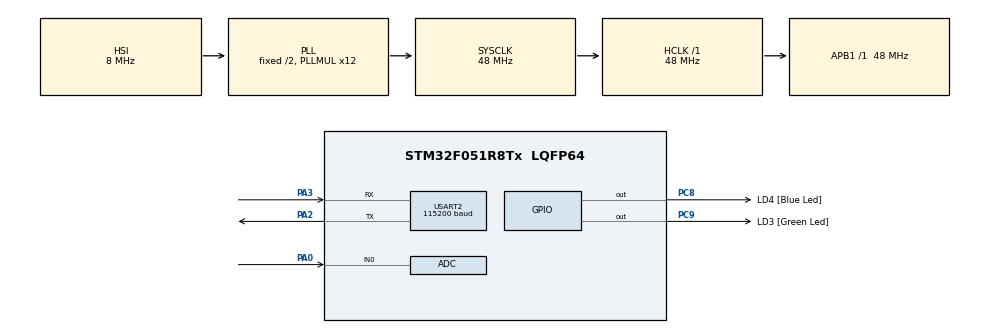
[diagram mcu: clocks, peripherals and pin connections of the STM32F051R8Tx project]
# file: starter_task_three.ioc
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Mcu.Family=STM32F0
Mcu.Name=STM32F051R8Tx
Mcu.Package=LQFP64
PA0.Mode=IN0
PA0.Signal=ADC_IN0
PA13.GPIO_Label=SWDIO
PA13.Mode=Serial_Wire
PA13.Signal=SYS_SWDIO
PA14.GPIO_Label=SWCLK
PA14.Mode=Serial_Wire
PA14.Signal=SYS_SWCLK
PA2.Mode=Asynchronous
PA2.Signal=USART2_TX
PA3.Mode=Asynchronous
PA3.Signal=USART2_RX
PC8.GPIO_Label=LD4 [Blue Led]
PC8.Signal=GPIO_Output
PC9.GPIO_Label=LD3 [Green Led]
PC9.Signal=GPIO_Output
ProjectManager.HeapSize=0x200
ProjectManager.StackSize=0x400
ProjectManager.TargetToolchain=STM32CubeIDE
RCC.AHBFreq_Value=48000000
RCC.APB1Freq_Value=48000000
RCC.APB1TimFreq_Value=48000000
RCC.HCLKFreq_Value=48000000
RCC.PLLMUL=RCC_PLL_MUL12
RCC.SYSCLKFreq_VALUE=48000000
RCC.SYSCLKSource=RCC_SYSCLKSOURCE_PLLCLK
RTC.Date=7
RTC.Hours=2
RTC.Minutes=50
RTC.Month=RTC_MONTH_MAY
RTC.WeekDay=RTC_WEEKDAY_TUESDAY
RTC.Year=24
USART2.BaudRate=115200
USART2.VirtualMode-Asynchronous=VM_ASYNC
VP_RTC_VS_RTC_Activate.Mode=RTC_Enabled
VP_RTC_VS_RTC_Calendar.Mode=RTC_Calendar
board=STM32F0DISCOVERY

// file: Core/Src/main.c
/* USER CODE BEGIN Header */
/**
  ******************************************************************************
  * @file           : main.c
  * @brief          : Main program body
  ******************************************************************************
  * @attention
  *
  * Copyright (c) 2024 STMicroelectronics.
  * All rights reserved.
  *
  * This software is licensed under terms that can be found in the LICENSE file
  * in the root directory of this software component.
  * If no LICENSE file comes with this software, it is provided AS-IS.
  *
  ******************************************************************************
  */
/* USER CODE END Header */
#include "main.h"

/* USER CODE BEGIN Includes */
#include <stdint.h>
#include <stdio.h>
#include <string.h>

/* USER CODE END Includes */

ADC_HandleTypeDef hadc;

RTC_HandleTypeDef hrtc;

UART_HandleTypeDef huart2;

void SystemClock_Config(void);
static void MX_GPIO_Init(void);
static void MX_RTC_Init(void);
static void MX_ADC_Init(void);
static void MX_USART2_UART_Init(void);

int main(void)
{

  /* MCU Configuration--------------------------------------------------------*/

  /* Reset of all peripherals, Initializes the Flash interface and the Systick. */
  HAL_Init();

  /* Configure the system clock */
  SystemClock_Config();

  /* Initialize all configured peripherals */
  MX_GPIO_Init();
  MX_RTC_Init();
  MX_ADC_Init();
  MX_USART2_UART_Init();
  /* USER CODE BEGIN 2 */
  char uart_buf[100];
  int uart_buf_len;
  uint8_t format = RTC_FORMAT_BIN;
  RTC_TimeTypeDef sTime = {0};
  RTC_DateTypeDef sDate = {0};

  /* USER CODE END 2 */

  /* Infinite loop */
  while (1)
  {

    /* USER CODE BEGIN 3 */
	  HAL_RTC_GetTime(&hrtc, &sTime, format);
	  HAL_RTC_GetDate(&hrtc, &sDate, format);
	  uart_buf_len = sprintf(uart_buf, "20%u-%u-%u %u:%u:%u\r\n", sDate.Year, sDate.Month,
			  sDate.Date, sTime.Hours, sTime.Minutes, sTime.Seconds);
	  HAL_UART_Transmit(&huart2, (uint8_t*)uart_buf, uart_buf_len, 1000);

	  HAL_Delay(500);
  }
  /* USER CODE END 3 */
}

void SystemClock_Config(void)
{
  RCC_OscInitTypeDef RCC_OscInitStruct = {0};
  RCC_ClkInitTypeDef RCC_ClkInitStruct = {0};
  RCC_PeriphCLKInitTypeDef PeriphClkInit = {0};

  /** Initializes the RCC Oscillators according to the specified parameters
  * in the RCC_OscInitTypeDef structure.
  */
  RCC_OscInitStruct.OscillatorType = RCC_OSCILLATORTYPE_HSI|RCC_OSCILLATORTYPE_HSI14
                              |RCC_OSCILLATORTYPE_LSI;
  RCC_OscInitStruct.HSIState = RCC_HSI_ON;
  RCC_OscInitStruct.HSI14State = RCC_HSI14_ON;
  RCC_OscInitStruct.HSICalibrationValue = RCC_HSICALIBRATION_DEFAULT;
  RCC_OscInitStruct.HSI14CalibrationValue = 16;
  RCC_OscInitStruct.LSIState = RCC_LSI_ON;
  RCC_OscInitStruct.PLL.PLLState = RCC_PLL_ON;
  RCC_OscInitStruct.PLL.PLLSource = RCC_PLLSOURCE_HSI;
  RCC_OscInitStruct.PLL.PLLMUL = RCC_PLL_MUL12;
  RCC_OscInitStruct.PLL.PREDIV = RCC_PREDIV_DIV1;
  if (HAL_RCC_OscConfig(&RCC_OscInitStruct) != HAL_OK)
  {
    Error_Handler();
  }

  /** Initializes the CPU, AHB and APB buses clocks
  */
  RCC_ClkInitStruct.ClockType = RCC_CLOCKTYPE_HCLK|RCC_CLOCKTYPE_SYSCLK
                              |RCC_CLOCKTYPE_PCLK1;
  RCC_ClkInitStruct.SYSCLKSource = RCC_SYSCLKSOURCE_PLLCLK;
  RCC_ClkInitStruct.AHBCLKDivider = RCC_SYSCLK_DIV1;
  RCC_ClkInitStruct.APB1CLKDivider = RCC_HCLK_DIV1;

  if (HAL_RCC_ClockConfig(&RCC_ClkInitStruct, FLASH_LATENCY_1) != HAL_OK)
  {
    Error_Handler();
  }
  PeriphClkInit.PeriphClockSelection = RCC_PERIPHCLK_RTC;
  PeriphClkInit.RTCClockSelection = RCC_RTCCLKSOURCE_LSI;
  if (HAL_RCCEx_PeriphCLKConfig(&PeriphClkInit) != HAL_OK)
  {
    Error_Handler();
  }
}

static void MX_ADC_Init(void)
{

  ADC_ChannelConfTypeDef sConfig = {0};

  /** Configure the global features of the ADC (Clock, Resolution, Data Alignment and number of conversion)
  */
  hadc.Instance = ADC1;
  hadc.Init.ClockPrescaler = ADC_CLOCK_ASYNC_DIV1;
  hadc.Init.Resolution = ADC_RESOLUTION_12B;
  hadc.Init.DataAlign = ADC_DATAALIGN_RIGHT;
  hadc.Init.ScanConvMode = ADC_SCAN_DIRECTION_FORWARD;
  hadc.Init.EOCSelection = ADC_EOC_SINGLE_CONV;
  hadc.Init.LowPowerAutoWait = DISABLE;
  hadc.Init.LowPowerAutoPowerOff = DISABLE;
  hadc.Init.ContinuousConvMode = DISABLE;
  hadc.Init.DiscontinuousConvMode = DISABLE;
  hadc.Init.ExternalTrigConv = ADC_SOFTWARE_START;
  hadc.Init.ExternalTrigConvEdge = ADC_EXTERNALTRIGCONVEDGE_NONE;
  hadc.Init.DMAContinuousRequests = DISABLE;
  hadc.Init.Overrun = ADC_OVR_DATA_PRESERVED;
  if (HAL_ADC_Init(&hadc) != HAL_OK)
  {
    Error_Handler();
  }

  /** Configure for the selected ADC regular channel to be converted.
  */
  sConfig.Channel = ADC_CHANNEL_0;
  sConfig.Rank = ADC_RANK_CHANNEL_NUMBER;
  sConfig.SamplingTime = ADC_SAMPLETIME_1CYCLE_5;
  if (HAL_ADC_ConfigChannel(&hadc, &sConfig) != HAL_OK)
  {
    Error_Handler();
  }

}

static void MX_RTC_Init(void)
{

  RTC_TimeTypeDef sTime = {0};
  RTC_DateTypeDef sDate = {0};

  /** Initialize RTC Only
  */
  hrtc.Instance = RTC;
  hrtc.Init.HourFormat = RTC_HOURFORMAT_24;
  hrtc.Init.AsynchPrediv = 127;
  hrtc.Init.SynchPrediv = 255;
  hrtc.Init.OutPut = RTC_OUTPUT_DISABLE;
  hrtc.Init.OutPutPolarity = RTC_OUTPUT_POLARITY_HIGH;
  hrtc.Init.OutPutType = RTC_OUTPUT_TYPE_OPENDRAIN;
  if (HAL_RTC_Init(&hrtc) != HAL_OK)
  {
    Error_Handler();
  }

  /** Initialize RTC and set the Time and Date
  */
  sTime.Hours = 0x2;
  sTime.Minutes = 0x50;
  sTime.Seconds = 0x0;
  sTime.DayLightSaving = RTC_DAYLIGHTSAVING_NONE;
  sTime.StoreOperation = RTC_STOREOPERATION_RESET;
  if (HAL_RTC_SetTime(&hrtc, &sTime, RTC_FORMAT_BCD) != HAL_OK)
  {
    Error_Handler();
  }
  sDate.WeekDay = RTC_WEEKDAY_TUESDAY;
  sDate.Month = RTC_MONTH_MAY;
  sDate.Date = 0x7;
  sDate.Year = 0x24;

  if (HAL_RTC_SetDate(&hrtc, &sDate, RTC_FORMAT_BCD) != HAL_OK)
  {
    Error_Handler();
  }

}

static void MX_USART2_UART_Init(void)
{

  huart2.Instance = USART2;
  huart2.Init.BaudRate = 115200;
  huart2.Init.WordLength = UART_WORDLENGTH_8B;
  huart2.Init.StopBits = UART_STOPBITS_1;
  huart2.Init.Parity = UART_PARITY_NONE;
  huart2.Init.Mode = UART_MODE_TX_RX;
  huart2.Init.HwFlowCtl = UART_HWCONTROL_NONE;
  huart2.Init.OverSampling = UART_OVERSAMPLING_16;
  huart2.Init.OneBitSampling = UART_ONE_BIT_SAMPLE_DISABLE;
  huart2.AdvancedInit.AdvFeatureInit = UART_ADVFEATURE_NO_INIT;
  if (HAL_UART_Init(&huart2) != HAL_OK)
  {
    Error_Handler();
  }

}

static void MX_GPIO_Init(void)
{
  GPIO_InitTypeDef GPIO_InitStruct = {0};

  /* GPIO Ports Clock Enable */
  __HAL_RCC_GPIOA_CLK_ENABLE();
  __HAL_RCC_GPIOC_CLK_ENABLE();

  /*Configure GPIO pin Output Level */
  HAL_GPIO_WritePin(GPIOC, LD4_Pin|LD3_Pin, GPIO_PIN_RESET);

  /*Configure GPIO pins : LD4_Pin LD3_Pin */
  GPIO_InitStruct.Pin = LD4_Pin|LD3_Pin;
  GPIO_InitStruct.Mode = GPIO_MODE_OUTPUT_PP;
  GPIO_InitStruct.Pull = GPIO_NOPULL;
  GPIO_InitStruct.Speed = GPIO_SPEED_FREQ_LOW;
  HAL_GPIO_Init(GPIOC, &GPIO_InitStruct);

}

void Error_Handler(void)
{
  __disable_irq();
  while (1)
  {
  }
}
